# GD32L23x register map
File version: 1.0
CPU: CM23 r0p0, little endian, MPU, FPU, 4 interrupt priority bits
Registers are 32-bit, read-write, reset 0x0 unless marked. A register's access mark holds for its fields unless they carry their own. Offsets are from the block's base; [hi:lo] are bit positions; {n}, {i} and the like mark numbered series.

## LPUART — Low-power Universal synchronous asynchronous receiver transmitter
Base 0x40008000
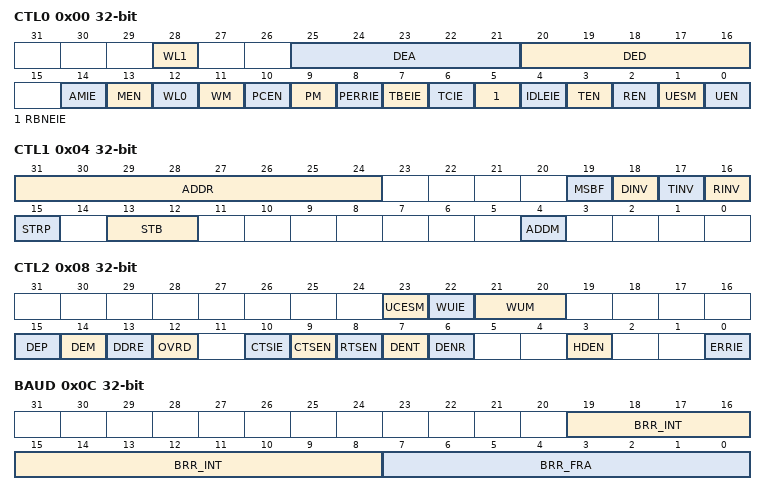
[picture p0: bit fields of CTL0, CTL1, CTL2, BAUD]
0x00 CTL0 — Control register 0
  [28] WL1 — Word length
  [25:21] DEA — Driver Enable assertion time
  [20:16] DED — Driver Enable deassertion time
  [14] AMIE — Character match interrupt enable
  [13] MEN — Mute mode enable
  [12] WL0 — Word length
  [11] WM — Receiver wakeup method
  [10] PCEN — Parity control enable
  [9] PM — Parity selection
  [8] PERRIE — PE interrupt enable
  [7] TBEIE — interrupt enable
  [6] TCIE — Transmission complete interrupt enable
  [5] RBNEIE — RXNE interrupt enable
  [4] IDLEIE — IDLE interrupt enable
  [3] TEN — Transmitter enable
  [2] REN — Receiver enable
  [1] UESM — LPUART enable in Deep-sleep mode
  [0] UEN — USART enable
0x04 CTL1 — Control register 1
  [31:24] ADDR — Address of the USART terminal
  [19] MSBF — Most significant bit first
  [18] DINV — Data bit level inversion
  [17] TINV — TX pin active level inversion
  [16] RINV — RX pin active level inversion
  [15] STRP — Swap TX/RX pins
  [13:12] STB — STOP bits
  [4] ADDM — 7-bit Address Detection/4-bit Address Detection
0x08 CTL2 — Control register 2
  [23] UCESM — LPUART clock enable in Deep-sleep mode
  [22] WUIE — Wakeup from Deep-sleep mode interrupt enable
  [21:20] WUM — Wakeup mode from Deep-sleep mode
  [15] DEP — Driver enable polarity selection
  [14] DEM — Driver enable mode
  [13] DDRE — DMA Disable on Reception Error
  [12] OVRD — Overrun Disable
  [10] CTSIE — CTS interrupt enable
  [9] CTSEN — CTS enable
  [8] RTSEN — RTS enable
  [7] DENT — DMA enable transmitter
  [6] DENR — DMA enable receiver
  [3] HDEN — Half-duplex selection
  [0] ERRIE — Error interrupt enable
0x0C BAUD — Baud rate low register
  [19:8] BRR_INT — integer of baud-rate divider
  [7:0] BRR_FRA — integer of baud-rate divider
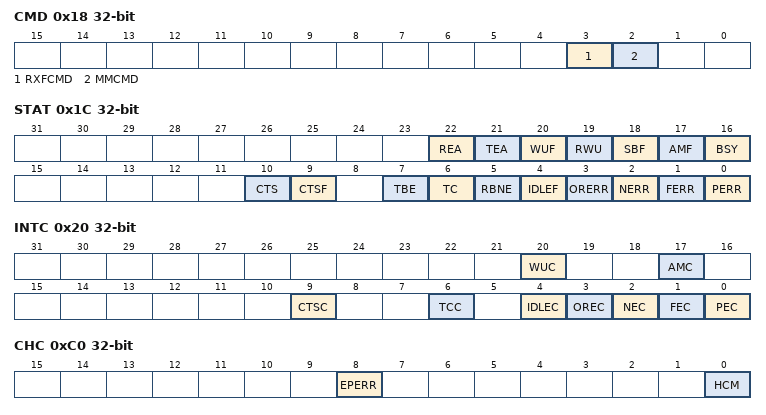
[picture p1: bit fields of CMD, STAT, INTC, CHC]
0x18 CMD wo — Command register
  [3] RXFCMD — Receive data flush command
  [2] MMCMD — Mute mode command
0x1C STAT ro — Status register
  [22] REA — Receive enable acknowledge flag
  [21] TEA — Transmit enable acknowledge flag
  [20] WUF — Wakeup from Deep-sleep mode flag
  [19] RWU — Receiver wakeup from mute mode
  [18] SBF — Send break flag
  [17] AMF — ADDR match flag
  [16] BSY — Busy flag
  [10] CTS — CTS leve
  [9] CTSF — CTS change flag
  [7] TBE — Transmit data register empty
  [6] TC — Transmission completed
  [5] RBNE — Read data buffer not empty
  [4] IDLEF — IDLE line detected flag
  [3] ORERR — Overrun error
  [2] NERR — Noise error flag
  [1] FERR — Frame error flag
  [0] PERR — Parity error flag
0x20 INTC wo — Interrupt status clear register
  [20] WUC — Wakeup from Deep-sleep mode flag clear
  [17] AMC — ADDR match flag clear
  [9] CTSC — CTS change clear
  [6] TCC — Transmission completed clear
  [4] IDLEC — IDLE line detected flag clear
  [3] OREC — Overrun error clear
  [2] NEC — Noise error flag clear
  [1] FEC — Frame error flag clear
  [0] PEC — Parity error flag clear
0x24 RDATA ro — Receive data register
  [8:0] RDATA — Parity error
0x28 TDATA — Transmit data register
  [8:0] TDATA — Transmit data value
0xC0 CHC — coherence control register
  [8] EPERR — Early parity error flag
  [0] HCM — Hardware flow control coherence mode

## CAU — Cryptographic acceleration unit
Base 0x50060000
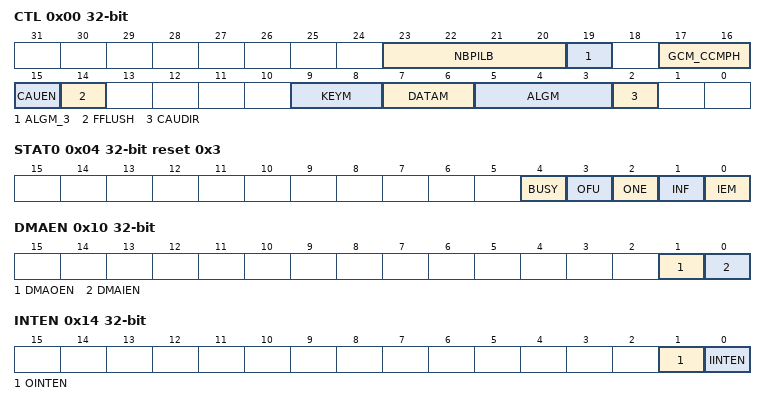
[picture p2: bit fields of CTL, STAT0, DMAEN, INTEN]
0x00 CTL access per field — CAU control register
  [23:20] NBPILB rw — Number of bytes padding in last block of payload
  [19] ALGM_3 rw — Encryption/decryption algorithm mode bit 3
  [17:16] GCM_CCMPH rw — GCM CCM phase
  [15] CAUEN rw — Cryptographic module enable
  [14] FFLUSH wo — FIFO flush
  [9:8] KEYM rw — AES key size mode configuration
  [7:6] DATAM rw — Data swapping type mode configuration
  [5:3] ALGM rw — Encryption/decryption algorithm mode
  [2] CAUDIR rw — CAU direction
0x04 STAT0 ro reset 0x3 — CAU status register 0
  [4] BUSY — BUSY flag
  [3] OFU — OUT FIFO full flag
  [2] ONE — OUT FIFO not empty flag
  [1] INF — IN FIFO not full flag
  [0] IEM — IN FIFO empty flag
0x08 DI — CAU data input register
  [31:0] DI — Data input
0x0C DO ro — CAU data output register
  [31:0] DO — Data output
0x10 DMAEN — CAU DMA enable register
  [1] DMAOEN — Out FIFO DMA enable
  [0] DMAIEN — In FIFO DMA enable
0x14 INTEN — CAU interrupt enable register
  [1] OINTEN — Out FIFO interrupt enable
  [0] IINTEN — In FIFO interrupt enable
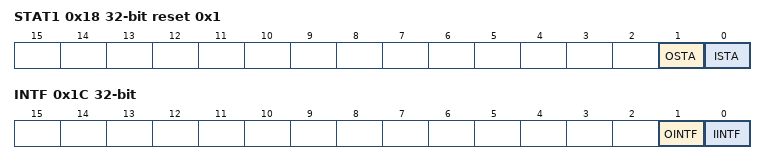
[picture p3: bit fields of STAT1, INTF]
0x18 STAT1 ro reset 0x1 — CAU interrupt status flag register 1
  [1] OSTA — Out FIFO interrupt flag
  [0] ISTA — In FIFO interrupt flag
0x1C INTF ro — CAU enable interrupt status flag register
  [1] OINTF — Out FIFO enabled interrupt flag
  [0] IINTF — In FIFO enabled interrupt flag
{0x20+8i} KEY{i}H wo (i=0..3) — CAU key register
  [31:0] KEY{i}H — Key for DES,TDES,AES
{0x24+8i} KEY{i}L wo (i=0..3) — CAU key register
  [31:0] KEY{i}L — Key for DES,TDES,AES
0x40 IV0H — CAU initialization register
  [31:0] IV0H — The initialization vector for DES,TDES,AES
0x44 IV0L — CAU initialization register
  [31:0] IV0L — The initialization vector for DES,TDES,AES
0x48 IV1H — CAU initialization register
  [31:0] IV1H — The initialization vector for DES,TDES,AES
0x4C IV1L — CAU initialization register
  [31:0] IV1L — The initialization vector for DES,TDES,AES
{0x50+4i} GCMCCMCTXS{i} (i=0..7) — GCM or CCM mode context switch register {i}
  [31:0] CTX{i} — The internal status of the CAU core
{0x70+4i} GCMCTXS{i} (i=0..7) — GCM mode context switch register {i}
  [31:0] CTX{i} — The internal status of the CAU core
